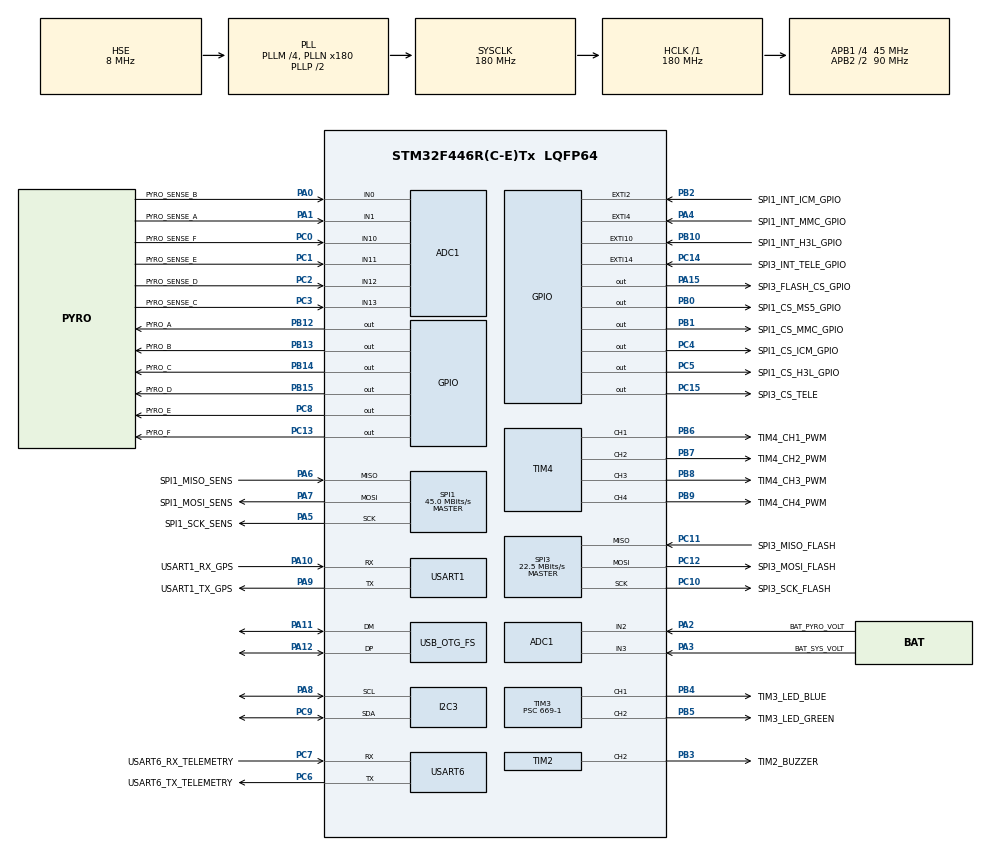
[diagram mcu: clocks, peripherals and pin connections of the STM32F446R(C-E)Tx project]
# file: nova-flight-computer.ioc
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ADC1.Channel-0\#ChannelRegularConversion=ADC_CHANNEL_0
ADC1.NbrOfConversionFlag=1
ADC1.Rank-0\#ChannelRegularConversion=1
ADC1.SamplingTime-0\#ChannelRegularConversion=ADC_SAMPLETIME_3CYCLES
ADC1.master=1
Mcu.Family=STM32F4
Mcu.Name=STM32F446R(C-E)Tx
Mcu.Package=LQFP64
NVIC.OTG_FS_IRQn=true\:0\:0\:false\:false\:true\:false\:true\:true
NVIC.PriorityGroup=NVIC_PRIORITYGROUP_4
PA0-WKUP.GPIO_Label=PYRO_SENSE_B
PA0-WKUP.Signal=ADCx_IN0
PA1.GPIO_Label=PYRO_SENSE_A
PA1.Signal=ADCx_IN1
PA10.GPIO_Label=USART1_RX_GPS
PA10.Mode=Asynchronous
PA10.Signal=USART1_RX
PA11.Mode=Device_Only
PA11.Signal=USB_OTG_FS_DM
PA12.Mode=Device_Only
PA12.Signal=USB_OTG_FS_DP
PA13.Mode=Serial_Wire
PA13.Signal=SYS_JTMS-SWDIO
PA14.Mode=Serial_Wire
PA14.Signal=SYS_JTCK-SWCLK
PA15.GPIO_Label=SPI3_FLASH_CS_GPIO
PA15.Signal=GPIO_Output
PA2.GPIO_Label=BAT_PYRO_VOLT
PA2.Signal=ADCx_IN2
PA3.GPIO_Label=BAT_SYS_VOLT
PA3.Signal=ADCx_IN3
PA4.GPIO_Label=SPI1_INT_MMC_GPIO
PA4.Signal=GPXTI4
PA5.GPIO_Label=SPI1_SCK_SENS
PA5.Mode=Full_Duplex_Master
PA5.Signal=SPI1_SCK
PA6.GPIO_Label=SPI1_MISO_SENS
PA6.Mode=Full_Duplex_Master
PA6.Signal=SPI1_MISO
PA7.GPIO_Label=SPI1_MOSI_SENS
PA7.Mode=Full_Duplex_Master
PA7.Signal=SPI1_MOSI
PA8.Mode=I2C
PA8.Signal=I2C3_SCL
PA9.GPIO_Label=USART1_TX_GPS
PA9.Mode=Asynchronous
PA9.Signal=USART1_TX
PB0.GPIO_Label=SPI1_CS_MS5_GPIO
PB0.Signal=GPIO_Output
PB1.GPIO_Label=SPI1_CS_MMC_GPIO
PB1.Signal=GPIO_Output
PB10.GPIO_Label=SPI1_INT_H3L_GPIO
PB10.Signal=GPXTI10
PB12.GPIO_Label=PYRO_A
PB12.Signal=GPIO_Output
PB13.GPIO_Label=PYRO_B
PB13.Signal=GPIO_Output
PB14.GPIO_Label=PYRO_C
PB14.Signal=GPIO_Output
PB15.GPIO_Label=PYRO_D
PB15.Signal=GPIO_Output
PB2.GPIO_Label=SPI1_INT_ICM_GPIO
PB2.Signal=GPXTI2
PB3.GPIO_Label=TIM2_BUZZER
PB3.Signal=S_TIM2_CH2
PB4.GPIO_Label=TIM3_LED_BLUE
PB4.Signal=S_TIM3_CH1
PB5.GPIO_Label=TIM3_LED_GREEN
PB5.Signal=S_TIM3_CH2
PB6.GPIO_Label=TIM4_CH1_PWM
PB6.Signal=S_TIM4_CH1
PB7.GPIO_Label=TIM4_CH2_PWM
PB7.Signal=S_TIM4_CH2
PB8.GPIO_Label=TIM4_CH3_PWM
PB8.Signal=S_TIM4_CH3
PB9.GPIO_Label=TIM4_CH4_PWM
PB9.Signal=S_TIM4_CH4
PC0.GPIO_Label=PYRO_SENSE_F
PC0.Signal=ADCx_IN10
PC1.GPIO_Label=PYRO_SENSE_E
PC1.Signal=ADCx_IN11
PC10.GPIO_Label=SPI3_SCK_FLASH
PC10.Mode=Full_Duplex_Master
PC10.Signal=SPI3_SCK
PC11.GPIO_Label=SPI3_MISO_FLASH
PC11.Mode=Full_Duplex_Master
PC11.Signal=SPI3_MISO
PC12.GPIO_Label=SPI3_MOSI_FLASH
PC12.Mode=Full_Duplex_Master
PC12.Signal=SPI3_MOSI
PC13.GPIO_Label=PYRO_F
PC13.Signal=GPIO_Output
PC14-OSC32_IN.GPIO_Label=SPI3_INT_TELE_GPIO
PC14-OSC32_IN.Signal=GPXTI14
PC15-OSC32_OUT.GPIO_Label=SPI3_CS_TELE
PC15-OSC32_OUT.Signal=GPIO_Output
PC2.GPIO_Label=PYRO_SENSE_D
PC2.Signal=ADCx_IN12
PC3.GPIO_Label=PYRO_SENSE_C
PC3.Signal=ADCx_IN13
PC4.GPIO_Label=SPI1_CS_ICM_GPIO
PC4.Signal=GPIO_Output
PC5.GPIO_Label=SPI1_CS_H3L_GPIO
PC5.Signal=GPIO_Output
PC6.GPIO_Label=USART6_TX_TELEMETRY
PC6.Mode=Asynchronous
PC6.Signal=USART6_TX
PC7.GPIO_Label=USART6_RX_TELEMETRY
PC7.Mode=Asynchronous
PC7.Signal=USART6_RX
PC8.GPIO_Label=PYRO_E
PC8.Signal=GPIO_Output
PC9.Mode=I2C
PC9.Signal=I2C3_SDA
PH0-OSC_IN.Mode=HSE-External-Oscillator
PH0-OSC_IN.Signal=RCC_OSC_IN
PH1-OSC_OUT.Mode=HSE-External-Oscillator
PH1-OSC_OUT.Signal=RCC_OSC_OUT
ProjectManager.HeapSize=0x200
ProjectManager.StackSize=0x400
ProjectManager.TargetToolchain=STM32CubeIDE
RCC.AHBFreq_Value=180000000
RCC.APB1CLKDivider=RCC_HCLK_DIV4
RCC.APB1Freq_Value=45000000
RCC.APB1TimFreq_Value=90000000
RCC.APB2CLKDivider=RCC_HCLK_DIV2
RCC.APB2Freq_Value=90000000
RCC.APB2TimFreq_Value=180000000
RCC.CortexFreq_Value=180000000
RCC.HCLKFreq_Value=180000000
RCC.HSE_VALUE=8000000
RCC.PLLM=4
RCC.PLLN=180
RCC.PLLQ=7
RCC.PLLSAIM=4
RCC.PLLSAIN=96
RCC.PLLSAIP=RCC_PLLSAIP_DIV4
RCC.SYSCLKFreq_VALUE=180000000
RCC.SYSCLKSource=RCC_SYSCLKSOURCE_PLLCLK
RCC.USBCLockSelection=RCC_CLK48CLKSOURCE_PLLSAIP
RCC.USBFreq_Value=48000000
RCC.VCOOutputFreq_Value=360000000
SH.ADCx_IN0.0=ADC1_IN0,IN0
SH.ADCx_IN1.0=ADC1_IN1,IN1
SH.ADCx_IN10.0=ADC1_IN10,IN10
SH.ADCx_IN11.0=ADC1_IN11,IN11
SH.ADCx_IN12.0=ADC1_IN12,IN12
SH.ADCx_IN13.0=ADC1_IN13,IN13
SH.ADCx_IN2.0=ADC1_IN2,IN2
SH.ADCx_IN3.0=ADC1_IN3,IN3
SH.S_TIM2_CH2.0=TIM2_CH2,PWM Generation2 CH2
SH.S_TIM3_CH1.0=TIM3_CH1,PWM Generation1 CH1
SH.S_TIM3_CH2.0=TIM3_CH2,PWM Generation2 CH2
SH.S_TIM4_CH1.0=TIM4_CH1,PWM Generation1 CH1
SH.S_TIM4_CH2.0=TIM4_CH2,PWM Generation2 CH2
SH.S_TIM4_CH3.0=TIM4_CH3,PWM Generation3 CH3
SH.S_TIM4_CH4.0=TIM4_CH4,PWM Generation4 CH4
SPI1.CalculateBaudRate=45.0 MBits/s
SPI1.Direction=SPI_DIRECTION_2LINES
SPI1.Mode=SPI_MODE_MASTER
SPI1.VirtualType=VM_MASTER
SPI3.CalculateBaudRate=22.5 MBits/s
SPI3.Direction=SPI_DIRECTION_2LINES
SPI3.Mode=SPI_MODE_MASTER
SPI3.VirtualType=VM_MASTER
TIM2.Channel-PWM\ Generation2\ CH2=TIM_CHANNEL_2
TIM2.Period=2048-1
TIM2.Prescaler=43-1
TIM3.Channel-PWM\ Generation1\ CH1=TIM_CHANNEL_1
TIM3.Channel-PWM\ Generation2\ CH2=TIM_CHANNEL_2
TIM3.Period=65536-1
TIM3.Prescaler=669-1
TIM4.Channel-PWM\ Generation1\ CH1=TIM_CHANNEL_1
TIM4.Channel-PWM\ Generation2\ CH2=TIM_CHANNEL_2
TIM4.Channel-PWM\ Generation3\ CH3=TIM_CHANNEL_3
TIM4.Channel-PWM\ Generation4\ CH4=TIM_CHANNEL_4
USART1.VirtualMode=VM_ASYNC
USART6.VirtualMode=VM_ASYNC
USB_DEVICE.CLASS_NAME_FS=CDC
USB_DEVICE.VirtualMode-CDC_FS=Cdc
USB_DEVICE.VirtualModeFS=Cdc_FS
USB_OTG_FS.VirtualMode=Device_Only
VP_ADC1_TempSens_Input.Mode=IN-TempSens
VP_TIM2_VS_ClockSourceINT.Mode=Internal
VP_TIM3_VS_ClockSourceINT.Mode=Internal
VP_TIM4_VS_ClockSourceINT.Mode=Internal
VP_USB_DEVICE_VS_USB_DEVICE_CDC_FS.Mode=CDC_FS
board=custom

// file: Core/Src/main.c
/* USER CODE BEGIN Header */
/**
  ******************************************************************************
  * @file           : main.c
  * @brief          : Main program body
  ******************************************************************************
  * @attention
  *
  * Copyright (c) 2022 STMicroelectronics.
  * All rights reserved.
  *
  * This software is licensed under terms that can be found in the LICENSE file
  * in the root directory of this software component.
  * If no LICENSE file comes with this software, it is provided AS-IS.
  *
  ******************************************************************************
  */
/* USER CODE END Header */
#include "main.h"
#include "usb_device.h"

/* USER CODE BEGIN Includes */
//#include "FLASH_SECTOR_F4.h"
#include "LED.h"
#include "BUZZER.h"
/* USER CODE END Includes */

 ADC_HandleTypeDef hadc1;

I2C_HandleTypeDef hi2c3;

SPI_HandleTypeDef hspi1;
SPI_HandleTypeDef hspi3;

TIM_HandleTypeDef htim2;
TIM_HandleTypeDef htim3;
TIM_HandleTypeDef htim4;

UART_HandleTypeDef huart1;
UART_HandleTypeDef huart6;

void SystemClock_Config(void);
static void MX_GPIO_Init(void);
static void MX_SPI1_Init(void);
static void MX_SPI3_Init(void);
static void MX_ADC1_Init(void);
static void MX_I2C3_Init(void);
static void MX_USART1_UART_Init(void);
static void MX_USART6_UART_Init(void);
static void MX_TIM2_Init(void);
static void MX_TIM3_Init(void);
static void MX_TIM4_Init(void);

/* USER CODE BEGIN 0 */
#define LED_BLUE TIM3->CCR1
#define LED_GREEN TIM3->CCR2
LED status_leds;
BUZZER buzzer;

/* USER CODE END 0 */

int main(void)
{

  /* MCU Configuration--------------------------------------------------------*/

  /* Reset of all peripherals, Initializes the Flash interface and the Systick. */
  HAL_Init();

  /* Configure the system clock */
  SystemClock_Config();

  /* Initialize all configured peripherals */
  MX_GPIO_Init();
  MX_SPI1_Init();
  MX_SPI3_Init();
  MX_USB_DEVICE_Init();
  MX_ADC1_Init();
  MX_I2C3_Init();
  MX_USART1_UART_Init();
  MX_USART6_UART_Init();
  MX_TIM2_Init();
  MX_TIM3_Init();
  MX_TIM4_Init();
  /* USER CODE BEGIN 2 */
  LED_init(&status_leds, &htim3);
  BUZZER_init(&buzzer, &htim2);

  LED_set_status(&status_leds, led_green, led_steady_on);
  LED_set_status(&status_leds, led_blue, led_slow_blink);
  buzzer.buzzer_tone = buzzer_fast_on_off;
  /* USER CODE END 2 */

  /* Infinite loop */
  while (1)
  {

    /* USER CODE BEGIN 3 */
	  if(HAL_GetTick() >= 5000)
	  {
		  buzzer.buzzer_tone = buzzer_off;
	  }
	  BUZZER_update(&buzzer);
  }
  /* USER CODE END 3 */
}

void SystemClock_Config(void)
{
  RCC_OscInitTypeDef RCC_OscInitStruct = {0};
  RCC_ClkInitTypeDef RCC_ClkInitStruct = {0};

  /** Configure the main internal regulator output voltage
  */
  __HAL_RCC_PWR_CLK_ENABLE();
  __HAL_PWR_VOLTAGESCALING_CONFIG(PWR_REGULATOR_VOLTAGE_SCALE1);

  /** Initializes the RCC Oscillators according to the specified parameters
  * in the RCC_OscInitTypeDef structure.
  */
  RCC_OscInitStruct.OscillatorType = RCC_OSCILLATORTYPE_HSE;
  RCC_OscInitStruct.HSEState = RCC_HSE_ON;
  RCC_OscInitStruct.PLL.PLLState = RCC_PLL_ON;
  RCC_OscInitStruct.PLL.PLLSource = RCC_PLLSOURCE_HSE;
  RCC_OscInitStruct.PLL.PLLM = 4;
  RCC_OscInitStruct.PLL.PLLN = 180;
  RCC_OscInitStruct.PLL.PLLP = RCC_PLLP_DIV2;
  RCC_OscInitStruct.PLL.PLLQ = 7;
  RCC_OscInitStruct.PLL.PLLR = 2;
  if (HAL_RCC_OscConfig(&RCC_OscInitStruct) != HAL_OK)
  {
    Error_Handler();
  }

  /** Activate the Over-Drive mode
  */
  if (HAL_PWREx_EnableOverDrive() != HAL_OK)
  {
    Error_Handler();
  }

  /** Initializes the CPU, AHB and APB buses clocks
  */
  RCC_ClkInitStruct.ClockType = RCC_CLOCKTYPE_HCLK|RCC_CLOCKTYPE_SYSCLK
                              |RCC_CLOCKTYPE_PCLK1|RCC_CLOCKTYPE_PCLK2;
  RCC_ClkInitStruct.SYSCLKSource = RCC_SYSCLKSOURCE_PLLCLK;
  RCC_ClkInitStruct.AHBCLKDivider = RCC_SYSCLK_DIV1;
  RCC_ClkInitStruct.APB1CLKDivider = RCC_HCLK_DIV4;
  RCC_ClkInitStruct.APB2CLKDivider = RCC_HCLK_DIV2;

  if (HAL_RCC_ClockConfig(&RCC_ClkInitStruct, FLASH_LATENCY_5) != HAL_OK)
  {
    Error_Handler();
  }
}

static void MX_ADC1_Init(void)
{

  ADC_ChannelConfTypeDef sConfig = {0};

  /** Configure the global features of the ADC (Clock, Resolution, Data Alignment and number of conversion)
  */
  hadc1.Instance = ADC1;
  hadc1.Init.ClockPrescaler = ADC_CLOCK_SYNC_PCLK_DIV4;
  hadc1.Init.Resolution = ADC_RESOLUTION_12B;
  hadc1.Init.ScanConvMode = DISABLE;
  hadc1.Init.ContinuousConvMode = DISABLE;
  hadc1.Init.DiscontinuousConvMode = DISABLE;
  hadc1.Init.ExternalTrigConvEdge = ADC_EXTERNALTRIGCONVEDGE_NONE;
  hadc1.Init.ExternalTrigConv = ADC_SOFTWARE_START;
  hadc1.Init.DataAlign = ADC_DATAALIGN_RIGHT;
  hadc1.Init.NbrOfConversion = 1;
  hadc1.Init.DMAContinuousRequests = DISABLE;
  hadc1.Init.EOCSelection = ADC_EOC_SINGLE_CONV;
  if (HAL_ADC_Init(&hadc1) != HAL_OK)
  {
    Error_Handler();
  }

  /** Configure for the selected ADC regular channel its corresponding rank in the sequencer and its sample time.
  */
  sConfig.Channel = ADC_CHANNEL_0;
  sConfig.Rank = 1;
  sConfig.SamplingTime = ADC_SAMPLETIME_3CYCLES;
  if (HAL_ADC_ConfigChannel(&hadc1, &sConfig) != HAL_OK)
  {
    Error_Handler();
  }

}

static void MX_I2C3_Init(void)
{

  hi2c3.Instance = I2C3;
  hi2c3.Init.ClockSpeed = 100000;
  hi2c3.Init.DutyCycle = I2C_DUTYCYCLE_2;
  hi2c3.Init.OwnAddress1 = 0;
  hi2c3.Init.AddressingMode = I2C_ADDRESSINGMODE_7BIT;
  hi2c3.Init.DualAddressMode = I2C_DUALADDRESS_DISABLE;
  hi2c3.Init.OwnAddress2 = 0;
  hi2c3.Init.GeneralCallMode = I2C_GENERALCALL_DISABLE;
  hi2c3.Init.NoStretchMode = I2C_NOSTRETCH_DISABLE;
  if (HAL_I2C_Init(&hi2c3) != HAL_OK)
  {
    Error_Handler();
  }

}

static void MX_SPI1_Init(void)
{

  /* SPI1 parameter configuration*/
  hspi1.Instance = SPI1;
  hspi1.Init.Mode = SPI_MODE_MASTER;
  hspi1.Init.Direction = SPI_DIRECTION_2LINES;
  hspi1.Init.DataSize = SPI_DATASIZE_8BIT;
  hspi1.Init.CLKPolarity = SPI_POLARITY_LOW;
  hspi1.Init.CLKPhase = SPI_PHASE_1EDGE;
  hspi1.Init.NSS = SPI_NSS_SOFT;
  hspi1.Init.BaudRatePrescaler = SPI_BAUDRATEPRESCALER_2;
  hspi1.Init.FirstBit = SPI_FIRSTBIT_MSB;
  hspi1.Init.TIMode = SPI_TIMODE_DISABLE;
  hspi1.Init.CRCCalculation = SPI_CRCCALCULATION_DISABLE;
  hspi1.Init.CRCPolynomial = 10;
  if (HAL_SPI_Init(&hspi1) != HAL_OK)
  {
    Error_Handler();
  }

}

static void MX_SPI3_Init(void)
{

  /* SPI3 parameter configuration*/
  hspi3.Instance = SPI3;
  hspi3.Init.Mode = SPI_MODE_MASTER;
  hspi3.Init.Direction = SPI_DIRECTION_2LINES;
  hspi3.Init.DataSize = SPI_DATASIZE_8BIT;
  hspi3.Init.CLKPolarity = SPI_POLARITY_LOW;
  hspi3.Init.CLKPhase = SPI_PHASE_1EDGE;
  hspi3.Init.NSS = SPI_NSS_SOFT;
  hspi3.Init.BaudRatePrescaler = SPI_BAUDRATEPRESCALER_2;
  hspi3.Init.FirstBit = SPI_FIRSTBIT_MSB;
  hspi3.Init.TIMode = SPI_TIMODE_DISABLE;
  hspi3.Init.CRCCalculation = SPI_CRCCALCULATION_DISABLE;
  hspi3.Init.CRCPolynomial = 10;
  if (HAL_SPI_Init(&hspi3) != HAL_OK)
  {
    Error_Handler();
  }

}

static void MX_TIM2_Init(void)
{

  TIM_ClockConfigTypeDef sClockSourceConfig = {0};
  TIM_MasterConfigTypeDef sMasterConfig = {0};
  TIM_OC_InitTypeDef sConfigOC = {0};

  htim2.Instance = TIM2;
  htim2.Init.Prescaler = 43-1;
  htim2.Init.CounterMode = TIM_COUNTERMODE_UP;
  htim2.Init.Period = 2048-1;
  htim2.Init.ClockDivision = TIM_CLOCKDIVISION_DIV1;
  htim2.Init.AutoReloadPreload = TIM_AUTORELOAD_PRELOAD_DISABLE;
  if (HAL_TIM_Base_Init(&htim2) != HAL_OK)
  {
    Error_Handler();
  }
  sClockSourceConfig.ClockSource = TIM_CLOCKSOURCE_INTERNAL;
  if (HAL_TIM_ConfigClockSource(&htim2, &sClockSourceConfig) != HAL_OK)
  {
    Error_Handler();
  }
  if (HAL_TIM_PWM_Init(&htim2) != HAL_OK)
  {
    Error_Handler();
  }
  sMasterConfig.MasterOutputTrigger = TIM_TRGO_RESET;
  sMasterConfig.MasterSlaveMode = TIM_MASTERSLAVEMODE_DISABLE;
  if (HAL_TIMEx_MasterConfigSynchronization(&htim2, &sMasterConfig) != HAL_OK)
  {
    Error_Handler();
  }
  sConfigOC.OCMode = TIM_OCMODE_PWM1;
  sConfigOC.Pulse = 0;
  sConfigOC.OCPolarity = TIM_OCPOLARITY_HIGH;
  sConfigOC.OCFastMode = TIM_OCFAST_DISABLE;
  if (HAL_TIM_PWM_ConfigChannel(&htim2, &sConfigOC, TIM_CHANNEL_2) != HAL_OK)
  {
    Error_Handler();
  }
  HAL_TIM_MspPostInit(&htim2);

}

static void MX_TIM3_Init(void)
{

  TIM_ClockConfigTypeDef sClockSourceConfig = {0};
  TIM_MasterConfigTypeDef sMasterConfig = {0};
  TIM_OC_InitTypeDef sConfigOC = {0};

  htim3.Instance = TIM3;
  htim3.Init.Prescaler = 669-1;
  htim3.Init.CounterMode = TIM_COUNTERMODE_UP;
  htim3.Init.Period = 65536-1;
  htim3.Init.ClockDivision = TIM_CLOCKDIVISION_DIV1;
  htim3.Init.AutoReloadPreload = TIM_AUTORELOAD_PRELOAD_DISABLE;
  if (HAL_TIM_Base_Init(&htim3) != HAL_OK)
  {
    Error_Handler();
  }
  sClockSourceConfig.ClockSource = TIM_CLOCKSOURCE_INTERNAL;
  if (HAL_TIM_ConfigClockSource(&htim3, &sClockSourceConfig) != HAL_OK)
  {
    Error_Handler();
  }
  if (HAL_TIM_PWM_Init(&htim3) != HAL_OK)
  {
    Error_Handler();
  }
  sMasterConfig.MasterOutputTrigger = TIM_TRGO_RESET;
  sMasterConfig.MasterSlaveMode = TIM_MASTERSLAVEMODE_DISABLE;
  if (HAL_TIMEx_MasterConfigSynchronization(&htim3, &sMasterConfig) != HAL_OK)
  {
    Error_Handler();
  }
  sConfigOC.OCMode = TIM_OCMODE_PWM1;
  sConfigOC.Pulse = 0;
  sConfigOC.OCPolarity = TIM_OCPOLARITY_HIGH;
  sConfigOC.OCFastMode = TIM_OCFAST_DISABLE;
  if (HAL_TIM_PWM_ConfigChannel(&htim3, &sConfigOC, TIM_CHANNEL_1) != HAL_OK)
  {
    Error_Handler();
  }
  if (HAL_TIM_PWM_ConfigChannel(&htim3, &sConfigOC, TIM_CHANNEL_2) != HAL_OK)
  {
    Error_Handler();
  }
  HAL_TIM_MspPostInit(&htim3);

}

static void MX_TIM4_Init(void)
{

  TIM_ClockConfigTypeDef sClockSourceConfig = {0};
  TIM_MasterConfigTypeDef sMasterConfig = {0};
  TIM_OC_InitTypeDef sConfigOC = {0};

  htim4.Instance = TIM4;
  htim4.Init.Prescaler = 0;
  htim4.Init.CounterMode = TIM_COUNTERMODE_UP;
  htim4.Init.Period = 65535;
  htim4.Init.ClockDivision = TIM_CLOCKDIVISION_DIV1;
  htim4.Init.AutoReloadPreload = TIM_AUTORELOAD_PRELOAD_DISABLE;
  if (HAL_TIM_Base_Init(&htim4) != HAL_OK)
  {
    Error_Handler();
  }
  sClockSourceConfig.ClockSource = TIM_CLOCKSOURCE_INTERNAL;
  if (HAL_TIM_ConfigClockSource(&htim4, &sClockSourceConfig) != HAL_OK)
  {
    Error_Handler();
  }
  if (HAL_TIM_PWM_Init(&htim4) != HAL_OK)
  {
    Error_Handler();
  }
  sMasterConfig.MasterOutputTrigger = TIM_TRGO_RESET;
  sMasterConfig.MasterSlaveMode = TIM_MASTERSLAVEMODE_DISABLE;
  if (HAL_TIMEx_MasterConfigSynchronization(&htim4, &sMasterConfig) != HAL_OK)
  {
    Error_Handler();
  }
  sConfigOC.OCMode = TIM_OCMODE_PWM1;
  sConfigOC.Pulse = 0;
  sConfigOC.OCPolarity = TIM_OCPOLARITY_HIGH;
  sConfigOC.OCFastMode = TIM_OCFAST_DISABLE;
  if (HAL_TIM_PWM_ConfigChannel(&htim4, &sConfigOC, TIM_CHANNEL_1) != HAL_OK)
  {
    Error_Handler();
  }
  if (HAL_TIM_PWM_ConfigChannel(&htim4, &sConfigOC, TIM_CHANNEL_2) != HAL_OK)
  {
    Error_Handler();
  }
  if (HAL_TIM_PWM_ConfigChannel(&htim4, &sConfigOC, TIM_CHANNEL_3) != HAL_OK)
  {
    Error_Handler();
  }
  if (HAL_TIM_PWM_ConfigChannel(&htim4, &sConfigOC, TIM_CHANNEL_4) != HAL_OK)
  {
    Error_Handler();
  }
  HAL_TIM_MspPostInit(&htim4);

}

static void MX_USART1_UART_Init(void)
{

  huart1.Instance = USART1;
  huart1.Init.BaudRate = 115200;
  huart1.Init.WordLength = UART_WORDLENGTH_8B;
  huart1.Init.StopBits = UART_STOPBITS_1;
  huart1.Init.Parity = UART_PARITY_NONE;
  huart1.Init.Mode = UART_MODE_TX_RX;
  huart1.Init.HwFlowCtl = UART_HWCONTROL_NONE;
  huart1.Init.OverSampling = UART_OVERSAMPLING_16;
  if (HAL_UART_Init(&huart1) != HAL_OK)
  {
    Error_Handler();
  }

}

static void MX_USART6_UART_Init(void)
{

  huart6.Instance = USART6;
  huart6.Init.BaudRate = 115200;
  huart6.Init.WordLength = UART_WORDLENGTH_8B;
  huart6.Init.StopBits = UART_STOPBITS_1;
  huart6.Init.Parity = UART_PARITY_NONE;
  huart6.Init.Mode = UART_MODE_TX_RX;
  huart6.Init.HwFlowCtl = UART_HWCONTROL_NONE;
  huart6.Init.OverSampling = UART_OVERSAMPLING_16;
  if (HAL_UART_Init(&huart6) != HAL_OK)
  {
    Error_Handler();
  }

}

static void MX_GPIO_Init(void)
{
  GPIO_InitTypeDef GPIO_InitStruct = {0};

  /* GPIO Ports Clock Enable */
  __HAL_RCC_GPIOC_CLK_ENABLE();
  __HAL_RCC_GPIOH_CLK_ENABLE();
  __HAL_RCC_GPIOA_CLK_ENABLE();
  __HAL_RCC_GPIOB_CLK_ENABLE();

  /*Configure GPIO pin Output Level */
  HAL_GPIO_WritePin(GPIOC, PYRO_F_Pin|SPI3_CS_TELE_Pin|SPI1_CS_ICM_GPIO_Pin|SPI1_CS_H3L_GPIO_Pin
                          |PYRO_E_Pin, GPIO_PIN_RESET);

  /*Configure GPIO pin Output Level */
  HAL_GPIO_WritePin(GPIOB, SPI1_CS_MS5_GPIO_Pin|SPI1_CS_MMC_GPIO_Pin|PYRO_A_Pin|PYRO_B_Pin
                          |PYRO_C_Pin|PYRO_D_Pin, GPIO_PIN_RESET);

  /*Configure GPIO pin Output Level */
  HAL_GPIO_WritePin(SPI3_FLASH_CS_GPIO_GPIO_Port, SPI3_FLASH_CS_GPIO_Pin, GPIO_PIN_RESET);

  /*Configure GPIO pins : PYRO_F_Pin SPI3_CS_TELE_Pin SPI1_CS_ICM_GPIO_Pin SPI1_CS_H3L_GPIO_Pin
                           PYRO_E_Pin */
  GPIO_InitStruct.Pin = PYRO_F_Pin|SPI3_CS_TELE_Pin|SPI1_CS_ICM_GPIO_Pin|SPI1_CS_H3L_GPIO_Pin
                          |PYRO_E_Pin;
  GPIO_InitStruct.Mode = GPIO_MODE_OUTPUT_PP;
  GPIO_InitStruct.Pull = GPIO_NOPULL;
  GPIO_InitStruct.Speed = GPIO_SPEED_FREQ_LOW;
  HAL_GPIO_Init(GPIOC, &GPIO_InitStruct);

  /*Configure GPIO pin : SPI3_INT_TELE_GPIO_Pin */
  GPIO_InitStruct.Pin = SPI3_INT_TELE_GPIO_Pin;
  GPIO_InitStruct.Mode = GPIO_MODE_IT_RISING;
  GPIO_InitStruct.Pull = GPIO_NOPULL;
  HAL_GPIO_Init(SPI3_INT_TELE_GPIO_GPIO_Port, &GPIO_InitStruct);

  /*Configure GPIO pin : SPI1_INT_MMC_GPIO_Pin */
  GPIO_InitStruct.Pin = SPI1_INT_MMC_GPIO_Pin;
  GPIO_InitStruct.Mode = GPIO_MODE_IT_RISING;
  GPIO_InitStruct.Pull = GPIO_NOPULL;
  HAL_GPIO_Init(SPI1_INT_MMC_GPIO_GPIO_Port, &GPIO_InitStruct);

  /*Configure GPIO pins : SPI1_CS_MS5_GPIO_Pin SPI1_CS_MMC_GPIO_Pin PYRO_A_Pin PYRO_B_Pin
                           PYRO_C_Pin PYRO_D_Pin */
  GPIO_InitStruct.Pin = SPI1_CS_MS5_GPIO_Pin|SPI1_CS_MMC_GPIO_Pin|PYRO_A_Pin|PYRO_B_Pin
                          |PYRO_C_Pin|PYRO_D_Pin;
  GPIO_InitStruct.Mode = GPIO_MODE_OUTPUT_PP;
  GPIO_InitStruct.Pull = GPIO_NOPULL;
  GPIO_InitStruct.Speed = GPIO_SPEED_FREQ_LOW;
  HAL_GPIO_Init(GPIOB, &GPIO_InitStruct);

  /*Configure GPIO pins : SPI1_INT_ICM_GPIO_Pin SPI1_INT_H3L_GPIO_Pin */
  GPIO_InitStruct.Pin = SPI1_INT_ICM_GPIO_Pin|SPI1_INT_H3L_GPIO_Pin;
  GPIO_InitStruct.Mode = GPIO_MODE_IT_RISING;
  GPIO_InitStruct.Pull = GPIO_NOPULL;
  HAL_GPIO_Init(GPIOB, &GPIO_InitStruct);

  /*Configure GPIO pin : SPI3_FLASH_CS_GPIO_Pin */
  GPIO_InitStruct.Pin = SPI3_FLASH_CS_GPIO_Pin;
  GPIO_InitStruct.Mode = GPIO_MODE_OUTPUT_PP;
  GPIO_InitStruct.Pull = GPIO_NOPULL;
  GPIO_InitStruct.Speed = GPIO_SPEED_FREQ_LOW;
  HAL_GPIO_Init(SPI3_FLASH_CS_GPIO_GPIO_Port, &GPIO_InitStruct);

}

void Error_Handler(void)
{
  __disable_irq();
  while (1)
  {
  }
}
